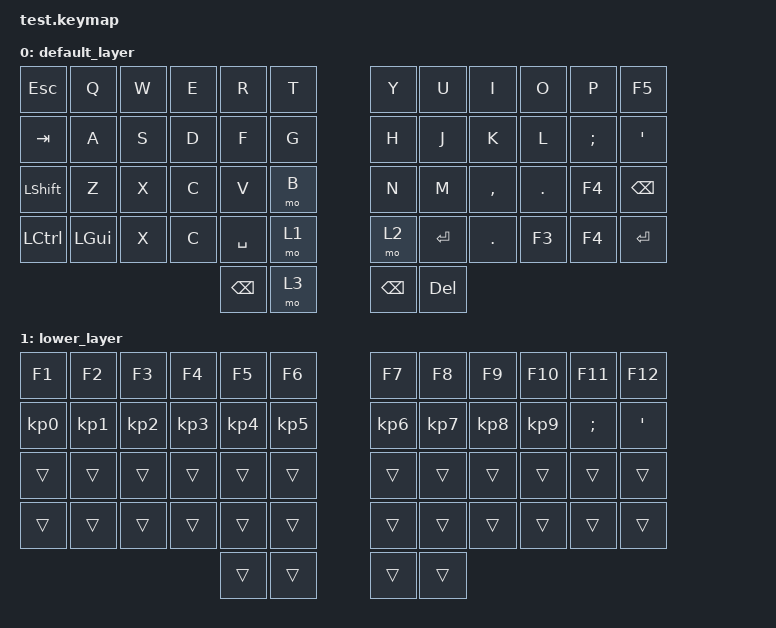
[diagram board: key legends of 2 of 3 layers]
#include <behaviors.dtsi>
#include <dt-bindings/zmk/keys.h>
#include <dt-bindings/zmk/bt.h>

/ {
    keymap {
        compatible = "zmk,keymap";
        default_layer {
// -----------------------------------------------------------------------------------------
// |  TAB |  Q  |  W  |  E  |  R  |  T  |   |  Y  |  U   |  I  |  O  |  P  | BSPC |
// | CTRL |  A  |  S  |  D  |  F  |  G  |   |  H  |  J   |  K  |  L  |  ;  |  '   |
// | SHFT |  Z  |  X  |  C  |  V  |  B  |   |  N  |  M   |  ,  |  .  |  /  | ESC  |
//                    | GUI | LWR | SPC |   | ENT | RSE  | ALT |
//            bindings = <
//   &kp TAB   &kp Q &kp W &kp E &kp R &kp T   &kp Y &kp U  &kp I     &kp O   &kp P    &kp BSPC
//   &kp LCTRL &kp A &kp S &kp D &kp F &kp G   &kp H &kp J  &kp K     &kp L   &kp SEMI &kp SQT
//   &kp LSHFT &kp Z &kp X &kp C &kp V &kp B   &kp N &kp M  &kp COMMA &kp DOT &kp FSLH &kp ESC
//                  &kp LGUI &mo 1 &kp SPACE   &kp RET &mo 2 &kp RALT
//            >;

            bindings = <
    //&kp ESC    &kp F1  &kp F2  &kp F3  &kp F4    &kp F5    &kp F6    &kp F7    &kp F8  &kp F9  &kp F10  &kp F11
    &kp ESC    &kp Q    &kp W   &kp E   &kp R     &kp T     &kp Y     &kp U     &kp I     &kp O   &kp P    &kp F5
    &kp TAB    &kp A    &kp S   &kp D   &kp F     &kp G     &kp H     &kp J     &kp K     &kp L   &kp SEMI &kp SQT
    &kp LSHFT  &kp Z    &kp X   &kp C   &kp V     &mo B     &kp N     &kp M     &kp COMMA &kp DOT &kp F4   &kp BSPC
    &kp LCTRL  &kp LGUI &kp X   &kp C   &kp SPACE &mo 1     &mo 2     &kp RET   &kp DOT   &kp F3  &kp F4   &kp RET
                                        &kp BSPC  &mo 3     &kp BSPC  &kp DEL
            >;
        };
        lower_layer {
            bindings = <
    &kp F1    &kp F2    &kp F3    &kp F4    &kp F5    &kp F6    &kp F7    &kp F8    &kp F9    &kp F10   &kp F11   &kp F12
    &kp KP_N0 &kp KP_N1 &kp KP_N2 &kp KP_N3 &kp KP_N4 &kp KP_N5 &kp KP_N6 &kp KP_N7 &kp KP_N8 &kp KP_N9 &kp SEMI  &kp SQT
    &trans    &trans    &trans    &trans    &trans    &trans    &trans    &trans    &trans    &trans    &trans    &trans
    &trans    &trans    &trans    &trans    &trans    &trans    &trans    &trans    &trans    &trans    &trans    &trans
                                            &trans    &trans    &trans    &trans
            >;
        };
            /*
        lowerer_layer {
// -----------------------------------------------------------------------------------------
// |  TAB |  1  |  2  |  3  |  4  |  5  |   |  6  |  7  |  8  |  9  |  0  | BSPC |
// | BTCLR| BT1 | BT2 | BT3 | BT4 | BT5 |   | LFT | DWN |  UP | RGT |     |      |
// | SHFT |     |     |     |     |     |   |     |     |     |     |     |      |
//                    | GUI |     | SPC |   | ENT |     | ALT |
            bindings = <
   &kp TAB    &kp N1       &kp N2       &kp N3       &kp N4       &kp N5         &kp N6   &kp N7   &kp N8 &kp N9    &kp N0 &kp BSPC
   &bt BT_CLR &bt BT_SEL 0 &bt BT_SEL 1 &bt BT_SEL 2 &bt BT_SEL 3 &bt BT_SEL 4   &kp LEFT &kp DOWN &kp UP &kp RIGHT &trans &trans
   &kp LSHFT  &trans       &trans       &trans       &trans       &trans         &trans   &trans   &trans &trans    &trans &trans
                                    &kp LGUI     &trans       &kp SPACE      &kp RET  &trans   &kp RALT
            >;
        };
            */

        raise_layer {
// -----------------------------------------------------------------------------------------
// |  TAB |  !  |  @  |  #  |  $  |  %  |   |  ^  |  &  |  *  |  (  |  )  | BSPC |
// | CTRL |     |     |     |     |     |   |  -  |  =  |  [  |  ]  |  \  |  `   |
// | SHFT |     |     |     |     |     |   |  _  |  +  |  {  |  }  | "|" |  ~   |
//                    | GUI |     | SPC |   | ENT |     | ALT |
            bindings = <
   &kp  TAB  &kp EXCL &kp AT &kp HASH &kp DLLR &kp PRCNT   &kp CARET &kp AMPS  &kp ASTRK &kp LPAR &kp RPAR &kp BSPC
   &kp LCTRL &trans   &trans &trans   &trans   &trans      &kp MINUS &kp EQUAL &kp LBKT  &kp RBKT &kp BSLH &kp GRAVE
   &kp LSHFT &trans   &trans &trans   &trans   &trans      &kp UNDER &kp PLUS  &kp LBRC  &kp RBRC &kp PIPE &kp TILDE
                             &kp LGUI &trans   &kp SPACE   &kp RET   &trans    &kp RALT
                >;
        };
    };
};
